# ATxmega32E5 device description
Architecture: AVR8_XMEGA; Family: AVR XMEGA
Registers are 8-bit, access not given, no defined reset value unless marked. A register's access mark holds for its fields unless they carry their own. Offsets are from the block's base; [hi:lo] are bit positions; {n}, {i} and the like mark numbered series; 'fields as' and 'values as' point back to an identical list.

## HIRES — High-Resolution Extension
Instances: HIRESC 0x8B0
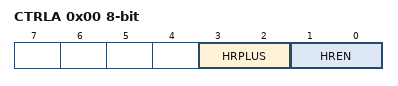
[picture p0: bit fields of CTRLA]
0x00 CTRLA — Control Register A
  [3:2] HRPLUS — High Resolution Plus
    0=NONE (No Hi-Res Plus); 1=HRP4 (Hi-Res Plus enabled on Timer 4); 2=HRP5 (Hi-Res Plus enabled on Timer 5); 3=BOTH (Hi-Res Plus enabled on Timer 4 and 5)
  [1:0] HREN — High Resolution Mode
    0=NONE (No Hi-Res); 1=HRP4 (Hi-Res enabled on Timer 4); 2=HRP5 (Hi-Res enabled on Timer 5); 3=BOTH (Hi-Res enabled on Timer 4 and 5)

## USART — Universal Synchronous/Asynchronous Receiver/Transmitter
Instances: USARTC0 0x8C0, USARTD0 0x9C0
0x00 DATA
0x01 STATUS
  [7] RXCIF — Receive Interrupt Flag
  [6] TXCIF — Transmit Interrupt Flag
  [5] DREIF — Data Register Empty Flag
  [4] FERR — Frame Error
  [3] BUFOVF — Buffer Overflow
  [2] PERR — Parity Error
  [1] RXSIF — Receive Start Bit Interrupt Flag
  [0] RXB8 — Receive Bit 8
  [0] DRIF — Data Reception Flag
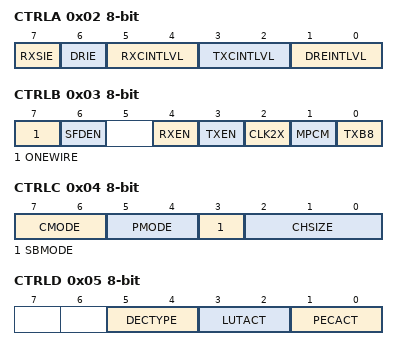
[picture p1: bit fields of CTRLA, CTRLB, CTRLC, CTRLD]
0x02 CTRLA — Control Register A
  [7] RXSIE — Receive Start Interrupt Enable
  [6] DRIE — Data Reception Interrupt Enable
  [5:4] RXCINTLVL — Receive Interrupt Level
    0=OFF (Interrupt Disabled); 1=LO (Low Level); 2=MED (Medium Level); 3=HI (High Level)
  [3:2] TXCINTLVL — Transmit Interrupt Level
    values as RXCINTLVL
  [1:0] DREINTLVL — Data Register Empty Interrupt Level
    values as RXCINTLVL
0x03 CTRLB — Control Register B
  [7] ONEWIRE — One Wire Mode
  [6] SFDEN — Start Frame Detection Enable
  [4] RXEN — Receiver Enable
  [3] TXEN — Transmitter Enable
  [2] CLK2X — Double transmission speed
  [1] MPCM — Multi-processor Communication Mode
  [0] TXB8 — Transmit bit 8
0x04 CTRLC — Control Register C
  [7:6] CMODE — Communication Mode
    0=ASYNCHRONOUS (Asynchronous Mode); 1=SYNCHRONOUS (Synchronous Mode); 2=IRDA (IrDA Mode); 3=MSPI (Master SPI Mode)
  [5:4] PMODE — Parity Mode
    0=DISABLED (No Parity); 2=EVEN (Even Parity); 3=ODD (Odd Parity)
  [3] SBMODE — Stop Bit Mode
  [2:0] CHSIZE — Character Size
    {v}={v+5}BIT (Character size: {v+5} bit) (v=0..3); 7=9BIT (Character size: 9 bit)
0x05 CTRLD — Control Register D
  [5:4] DECTYPE — Receive Interrupt Level
    0=DATA (DATA Field Encoding); 2=SDATA (Start and Data Fields Encoding); 3=NOTSDATA (Start and Data Fields Encoding, with invertion in START field)
  [3:2] LUTACT — Transmit Interrupt Level
    0=OFF (Standard Frame Configuration); 1=RX (Receiver Decoding Enabled); 2=TX (Transmitter Encoding Enabled); 3=BOTH (Both Encoding and Decoding Enabled)
  [1:0] PECACT — Data Register Empty Interrupt Level
    0=OFF (Standard Mode); 1=PEC0 (Variable Data Lenght in Reception); 2=PEC1 (Variable Data Lenght in Transmission); 3=PERC01 (Variable Data Lenght in both Reception and Transmission)
0x06 BAUDCTRLA — Baud Rate Control Register A
  [7:0] BSEL — Baud Rate Selection Bits [7:0]
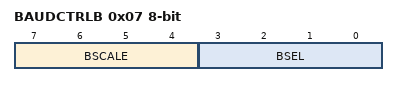
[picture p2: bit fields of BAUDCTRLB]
0x07 BAUDCTRLB — Baud Rate Control Register B
  [7:4] BSCALE — Baud Rate Scale
  [3:0] BSEL — Baud Rate Selection bits[11:8]

## SPI — Serial Peripheral Interface with Buffer Modes
Instances: SPIC 0x08E0
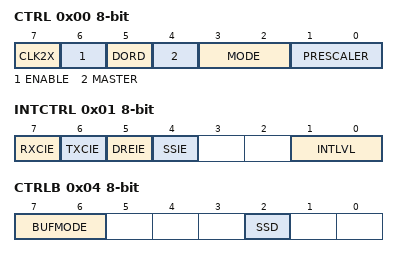
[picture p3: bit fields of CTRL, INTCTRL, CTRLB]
0x00 CTRL — Control Register
  [7] CLK2X — Enable Double Speed
  [6] ENABLE — Enable SPI Module
  [5] DORD — Data Order Setting
  [4] MASTER — Master Operation Enable
  [3:2] MODE — SPI Mode
    0=SPI Mode 0, base clock at "0", sampling on leading edge (rising) & set-up on trailling edge (falling); 1=SPI Mode 1, base clock at "0", set-up on leading edge (rising) & sampling on trailling edge (falling); 2=SPI Mode 2, base clock at "1", sampling on leading edge (falling) & set-up on trailling edge (rising); 3=SPI Mode 3, base clock at "1", set-up on leading edge (falling) & sampling on trailling edge (rising)
  [1:0] PRESCALER
    0=DIV4 (If CLK2X=1 CLKper/2, else (CLK2X=0) CLKper/4.); 1=DIV16 (If CLK2X=1 CLKper/8, else (CLK2X=0) CLKper/16.); 2=DIV64 (If CLK2X=1 CLKper/32, else (CLK2X=0) CLKper/64.); 3=DIV128 (If CLK2X=1 CLKper/64, else (CLK2X=0) CLKper/128.)
0x01 INTCTRL — Interrupt Control Register
  [7] RXCIE — Receive Complete Interrupt Enable (In Buffer Modes Only).
  [6] TXCIE — Transmit Complete Interrupt Enable (In Buffer Modes Only).
  [5] DREIE — Data Register Empty Interrupt Enable (In Buffer Modes Only).
  [4] SSIE — Slave Select Trigger Interrupt Enable (In Buffer Modes Only).
  [1:0] INTLVL — Interrupt level
    0=OFF (Interrupt Disabled); 1=LO (Low Level); 2=MED (Medium Level); 3=HI (High Level)
0x02 STATUS
  [7] IF — Interrupt Flag (In Standard Mode Only).
  [7] RXCIF — Receive Complete Interrupt Flag (In Buffer Modes Only).
  [6] WRCOL — Write Collision Flag (In Standard Mode Only).
  [6] TXCIF — Transmit Complete Interrupt Flag (In Buffer Modes Only).
  [5] DREIF — Data Register Empty Interrupt Flag (In Buffer Modes Only).
  [4] SSIF — Slave Select Trigger Interrupt Flag (In Buffer Modes Only).
  [0] BUFOVF — Buffer Overflow (In Buffer Modes Only).
0x03 DATA
0x04 CTRLB — Control Register B
  [7:6] BUFMODE — Buffer Modes
    0=OFF (SPI Unbuffered Mode); 2=Buffer Mode 1 (with dummy byte); 3=Buffer Mode 2 (no dummy byte)
  [2] SSD — Slave Select Disable
